# IPU2_UNICACHE_CFG register map
Vendor: Texas Instruments
Peripheral module from a debugger description file (folder DRA75x_DRA74x).
Registers are 32-bit, read-write, reset 0x0 unless marked. A register's access mark holds for its fields unless they carry their own. Offsets are as the file gives them; lines under a group give offsets from that group; [hi:lo] are bit positions; {n}, {i} and the like mark numbered series; 'fields as' and 'values as' point back to an identical list; <NAME> marks a mode.

## IPU2_UNICACHE_CFG
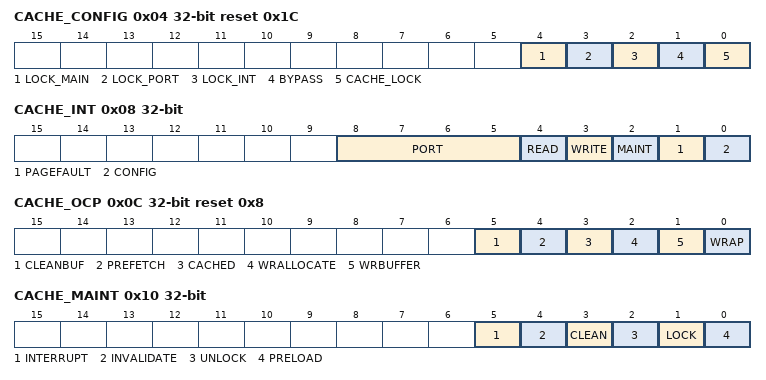
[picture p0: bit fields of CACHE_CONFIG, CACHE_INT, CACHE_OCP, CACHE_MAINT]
0x04 CACHE_CONFIG access per field reset 0x1C — Configuration Register
  [4] LOCK_MAIN rw — Lock access to maintenance registers
    0=Locked; 1=Not_locked
  [3] LOCK_PORT rw — Lock access to interface registers
    0=Locked; 1=Not_locked
  [2] LOCK_INT rw — Lock access to interrupt registers
    0=Locked; 1=Not_locked
  [1] BYPASS rw — Bypass cache
    0=Everything_is_non-cacheable; 1=Everything_is_cacheable
  [0] CACHE_LOCK rw — Unicache lock. Once this bit is set only debugger or hardware reset can clear.
    0=No_effect; 1=Only_debug_accesses_allowed
0x08 CACHE_INT access not given — Interrupt Register
  [8:5] PORT — Slave interface number that has recorded an error (access RW W1toClr)
  [4] READ — Interface read response error (access RW W1toClr)
  [3] WRITE — Interface write response error (access RW W1toClr)
  [2] MAINT — Maintenance is completed (access RW W1toClr)
  [1] PAGEFAULT — Unicache MMU page fault (access RW W1toClr)
  [0] CONFIG — Configuration error (access RW W1toClr)
0x0C CACHE_OCP access per field reset 0x8 — Interface Configuration Register
  [5] CLEANBUF rw — Clean write and prefetch buffers in cache
    0=Do_not_clean; 1=Clean
  [4] PREFETCH rw — Always prefetch data
    0=Follow_MMU_policies; 1=Always_prefetch
  [3] CACHED rw — Follow cacheable sideband signals
    0=Reads always not allocated, writes write through if cached; 1=Slave_sideband_signals_determine_policy
  [2] WRALLOCATE rw — Follow write allocate sideband signals
    0=No writes are allocated independent to sideband; 1=Follow_sideband
  [1] WRBUFFER rw — Write throughs and write back no allocate are buffered
    0=Write throughs and write back no allocated are not buffered; 1=Write throughs and write back no allocated are buffered
  [0] WRAP rw — OCP wrap mode (critical word first)
    0=Disabled; 1=Enabled
0x10 CACHE_MAINT access per field — Maintenance Configuration Register
  [5] INTERRUPT rw — Generate interrupt when maintenance operation is complete
    0=Do_not_generate_interrupt; 1=Generate_interrupt
  [4] INVALIDATE rw — Invalidate lines in region defined by maintenance start/end addresses
    0=Do_nothing; 1=Invalidate
  [3] CLEAN rw — Evict dirty lines in region defined by maintenance start/end addresses
    0=Do_nothing; 1=Clean
  [2] UNLOCK rw — Unlock region defined by maintenance start/end addresses
    0=Do_nothing; 1=Unlock
  [1] LOCK rw — Lock region defined by maintenance start/end addresses
    0=Do_nothing; 1=Lock
  [0] PRELOAD rw — Preload region defined by maintenance start/end addresses
    0=Do_nothing; 1=Preload
0x14 CACHE_MTSTART — Maintenance Start Configuration Register
  [31:0] START_ADDR — Start address of maintenance operations, reset to 0x0000 0000 when finished
0x18 CACHE_MTEND — Maintenance End Configuration Register
  [31:0] END_ADDR — End address of maintenance operations, reset to 0x0000 0000 when finished
0x1C CACHE_CTADDR — Cache Test Address Register
  [31:0] ADDRESS — Address of cache visibility when readCACHE_CTDATA register, autoincrements
0x20 CACHE_CTDATA — Cache Test Data Register
  [31:0] DATA — Cache data at address ofCACHE_CTADDR register, CACHE_CTADDR autoincrements each time CACHE_CTDATA is read
